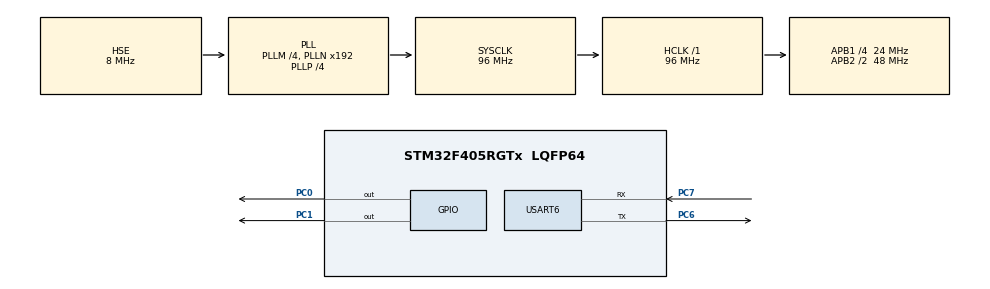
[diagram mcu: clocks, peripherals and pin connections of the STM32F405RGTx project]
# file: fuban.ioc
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Dma.MEMTOMEM.2.Direction=DMA_MEMORY_TO_MEMORY
Dma.MEMTOMEM.2.FIFOMode=DMA_FIFOMODE_ENABLE
Dma.MEMTOMEM.2.FIFOThreshold=DMA_FIFO_THRESHOLD_FULL
Dma.MEMTOMEM.2.Instance=DMA2_Stream0
Dma.MEMTOMEM.2.MemBurst=DMA_MBURST_SINGLE
Dma.MEMTOMEM.2.MemDataAlignment=DMA_MDATAALIGN_BYTE
Dma.MEMTOMEM.2.MemInc=DMA_MINC_ENABLE
Dma.MEMTOMEM.2.Mode=DMA_NORMAL
Dma.MEMTOMEM.2.PeriphBurst=DMA_PBURST_SINGLE
Dma.MEMTOMEM.2.PeriphDataAlignment=DMA_PDATAALIGN_BYTE
Dma.MEMTOMEM.2.PeriphInc=DMA_PINC_ENABLE
Dma.MEMTOMEM.2.Priority=DMA_PRIORITY_LOW
Dma.Request0=USART6_RX
Dma.Request1=USART6_TX
Dma.Request2=MEMTOMEM
Dma.USART6_RX.0.Direction=DMA_PERIPH_TO_MEMORY
Dma.USART6_RX.0.FIFOMode=DMA_FIFOMODE_DISABLE
Dma.USART6_RX.0.Instance=DMA2_Stream1
Dma.USART6_RX.0.MemDataAlignment=DMA_MDATAALIGN_BYTE
Dma.USART6_RX.0.MemInc=DMA_MINC_ENABLE
Dma.USART6_RX.0.Mode=DMA_NORMAL
Dma.USART6_RX.0.PeriphDataAlignment=DMA_PDATAALIGN_BYTE
Dma.USART6_RX.0.PeriphInc=DMA_PINC_DISABLE
Dma.USART6_RX.0.Priority=DMA_PRIORITY_MEDIUM
Dma.USART6_TX.1.Direction=DMA_MEMORY_TO_PERIPH
Dma.USART6_TX.1.FIFOMode=DMA_FIFOMODE_DISABLE
Dma.USART6_TX.1.Instance=DMA2_Stream6
Dma.USART6_TX.1.MemDataAlignment=DMA_MDATAALIGN_BYTE
Dma.USART6_TX.1.MemInc=DMA_MINC_ENABLE
Dma.USART6_TX.1.Mode=DMA_NORMAL
Dma.USART6_TX.1.PeriphDataAlignment=DMA_PDATAALIGN_BYTE
Dma.USART6_TX.1.PeriphInc=DMA_PINC_DISABLE
Dma.USART6_TX.1.Priority=DMA_PRIORITY_MEDIUM
Mcu.Family=STM32F4
Mcu.Name=STM32F405RGTx
Mcu.Package=LQFP64
NVIC.DMA2_Stream1_IRQn=true\:0\:0\:false\:false\:true\:false\:true
NVIC.DMA2_Stream6_IRQn=true\:0\:0\:false\:false\:true\:false\:true
NVIC.PriorityGroup=NVIC_PRIORITYGROUP_4
NVIC.USART6_IRQn=true\:0\:0\:false\:false\:true\:true\:true
PC0.Signal=GPIO_Output
PC1.Signal=GPIO_Output
PC6.Mode=Asynchronous
PC6.Signal=USART6_TX
PC7.Mode=Asynchronous
PC7.Signal=USART6_RX
PH0-OSC_IN.Mode=HSE-External-Oscillator
PH0-OSC_IN.Signal=RCC_OSC_IN
PH1-OSC_OUT.Mode=HSE-External-Oscillator
PH1-OSC_OUT.Signal=RCC_OSC_OUT
ProjectManager.HeapSize=0x200
ProjectManager.StackSize=0x400
ProjectManager.TargetToolchain=MDK-ARM V5.27
RCC.48MHZClocksFreq_Value=96000000
RCC.AHBFreq_Value=96000000
RCC.APB1CLKDivider=RCC_HCLK_DIV4
RCC.APB1Freq_Value=24000000
RCC.APB1TimFreq_Value=48000000
RCC.APB2CLKDivider=RCC_HCLK_DIV2
RCC.APB2Freq_Value=48000000
RCC.APB2TimFreq_Value=96000000
RCC.CortexFreq_Value=96000000
RCC.HCLKFreq_Value=96000000
RCC.HSE_VALUE=8000000
RCC.HSI_VALUE=16000000
RCC.LSE_VALUE=32768
RCC.PLLM=4
RCC.PLLP=RCC_PLLP_DIV4
RCC.PLLSourceVirtual=RCC_PLLSOURCE_HSE
RCC.SYSCLKFreq_VALUE=96000000
RCC.SYSCLKSource=RCC_SYSCLKSOURCE_PLLCLK
RCC.VCOOutputFreq_Value=384000000
USART6.VirtualMode=VM_ASYNC
USART6.WordLength=WORDLENGTH_9B
board=custom

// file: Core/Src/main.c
/* USER CODE BEGIN Header */
/**
  ******************************************************************************
  * @file           : main.c
  * @brief          : Main program body
  ******************************************************************************
  * @attention
  *
  * <h2><center>&copy; Copyright (c) 2021 STMicroelectronics.
  * All rights reserved.</center></h2>
  *
  * This software component is licensed by ST under BSD 3-Clause license,
  * the "License"; You may not use this file except in compliance with the
  * License. You may obtain a copy of the License at:
  *                        opensource.org/licenses/BSD-3-Clause
  *
  ******************************************************************************
  */
/* USER CODE END Header */
#include "main.h"
#include "dma.h"
#include "usart.h"
#include "gpio.h"

/* USER CODE BEGIN PV */
extern uint8_t RX ;
extern volatile uint8_t rx_len;  //接收一帧数据的长度
extern volatile uint8_t recv_end_flag; //一帧数据接收完成标志
/* USER CODE END PV */

void SystemClock_Config(void);

int main(void)
{

  /* MCU Configuration--------------------------------------------------------*/

  /* Reset of all peripherals, Initializes the Flash interface and the Systick. */
  HAL_Init();

  /* Configure the system clock */
  SystemClock_Config();

  /* Initialize all configured peripherals */
  MX_GPIO_Init();
  MX_DMA_Init();
  MX_USART6_UART_Init();
  /* USER CODE BEGIN 2 */
	__HAL_UART_ENABLE_IT ( &huart6 , UART_IT_IDLE ) ;
	HAL_UART_Receive_DMA(&huart6,(uint8_t *)RX,sizeof(RX));
//HAL_UART_Receive_IT(&huart6, TX, 10);
//HAL_UART_Receive(&huart6, TX, 10,1000);
  /* USER CODE END 2 */

  /* Infinite loop */
  while (1)
  {

  }
}

void SystemClock_Config(void)
{
  RCC_OscInitTypeDef RCC_OscInitStruct = {0};
  RCC_ClkInitTypeDef RCC_ClkInitStruct = {0};

  /** Configure the main internal regulator output voltage
  */
  __HAL_RCC_PWR_CLK_ENABLE();
  __HAL_PWR_VOLTAGESCALING_CONFIG(PWR_REGULATOR_VOLTAGE_SCALE1);
  /** Initializes the RCC Oscillators according to the specified parameters
  * in the RCC_OscInitTypeDef structure.
  */
  RCC_OscInitStruct.OscillatorType = RCC_OSCILLATORTYPE_HSE;
  RCC_OscInitStruct.HSEState = RCC_HSE_ON;
  RCC_OscInitStruct.PLL.PLLState = RCC_PLL_ON;
  RCC_OscInitStruct.PLL.PLLSource = RCC_PLLSOURCE_HSE;
  RCC_OscInitStruct.PLL.PLLM = 4;
  RCC_OscInitStruct.PLL.PLLN = 192;
  RCC_OscInitStruct.PLL.PLLP = RCC_PLLP_DIV4;
  RCC_OscInitStruct.PLL.PLLQ = 4;
  if (HAL_RCC_OscConfig(&RCC_OscInitStruct) != HAL_OK)
  {
    Error_Handler();
  }
  /** Initializes the CPU, AHB and APB buses clocks
  */
  RCC_ClkInitStruct.ClockType = RCC_CLOCKTYPE_HCLK|RCC_CLOCKTYPE_SYSCLK
                              |RCC_CLOCKTYPE_PCLK1|RCC_CLOCKTYPE_PCLK2;
  RCC_ClkInitStruct.SYSCLKSource = RCC_SYSCLKSOURCE_PLLCLK;
  RCC_ClkInitStruct.AHBCLKDivider = RCC_SYSCLK_DIV1;
  RCC_ClkInitStruct.APB1CLKDivider = RCC_HCLK_DIV4;
  RCC_ClkInitStruct.APB2CLKDivider = RCC_HCLK_DIV2;

  if (HAL_RCC_ClockConfig(&RCC_ClkInitStruct, FLASH_LATENCY_3) != HAL_OK)
  {
    Error_Handler();
  }
}

/* USER CODE BEGIN 4 */
void DMA_Usart1_Read(uint8_t *Data,uint8_t len)//串口接收封装
{
	HAL_UART_Receive_DMA(&huart6,Data,len);//重新打开DMA接收
}
/* USER CODE END 4 */

void Error_Handler(void)
{
  __disable_irq();
  while (1)
  {
  }
}

/************************ (C) COPYRIGHT STMicroelectronics *****END OF FILE****/
